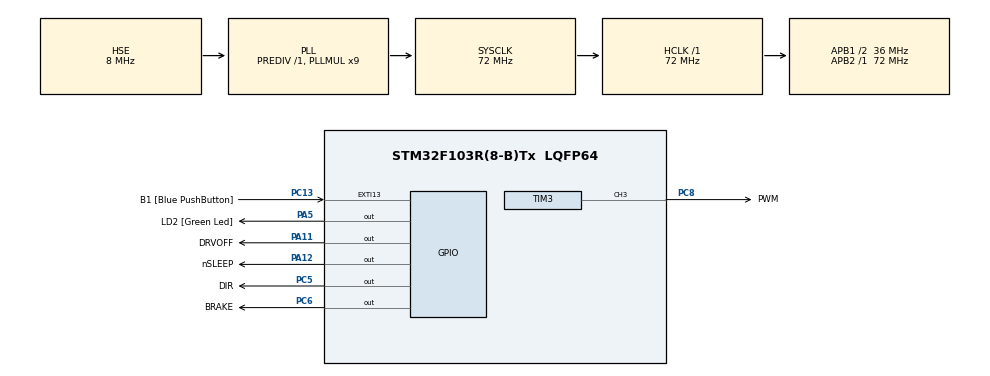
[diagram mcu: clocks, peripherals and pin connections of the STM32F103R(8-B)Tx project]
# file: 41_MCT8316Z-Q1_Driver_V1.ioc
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Mcu.Family=STM32F1
Mcu.Name=STM32F103R(8-B)Tx
Mcu.Package=LQFP64
NVIC.EXTI15_10_IRQn=true\:0\:0\:false\:false\:true\:true\:true\:true
NVIC.PriorityGroup=NVIC_PRIORITYGROUP_4
PA11.GPIO_Label=DRVOFF
PA11.Signal=GPIO_Output
PA12.GPIO_Label=nSLEEP
PA12.Signal=GPIO_Output
PA13.GPIO_Label=TMS
PA13.Mode=JTAG_5_pins
PA13.Signal=SYS_JTMS-SWDIO
PA14.GPIO_Label=TCK
PA14.Mode=JTAG_5_pins
PA14.Signal=SYS_JTCK-SWCLK
PA15.Mode=JTAG_5_pins
PA15.Signal=SYS_JTDI
PA5.GPIO_Label=LD2 [Green Led]
PA5.GPIO_ModeDefaultOutputPP=GPIO_MODE_OUTPUT_PP
PA5.GPIO_PuPd=GPIO_NOPULL
PA5.GPIO_Speed=GPIO_SPEED_FREQ_LOW
PA5.Signal=GPIO_Output
PB3.Mode=JTAG_5_pins
PB3.Signal=SYS_JTDO-TRACESWO
PB4.Mode=JTAG_5_pins
PB4.Signal=SYS_NJTRST
PC13-TAMPER-RTC.GPIO_Label=B1 [Blue PushButton]
PC13-TAMPER-RTC.GPIO_PuPd=GPIO_NOPULL
PC13-TAMPER-RTC.Signal=GPXTI13
PC14-OSC32_IN.Mode=LSE-External-Oscillator
PC14-OSC32_IN.Signal=RCC_OSC32_IN
PC15-OSC32_OUT.Mode=LSE-External-Oscillator
PC15-OSC32_OUT.Signal=RCC_OSC32_OUT
PC5.GPIO_Label=DIR
PC5.Signal=GPIO_Output
PC6.GPIO_Label=BRAKE
PC6.Signal=GPIO_Output
PC8.GPIO_Label=PWM
PC8.Signal=S_TIM3_CH3
PD0-OSC_IN.Mode=HSE-External-Oscillator
PD0-OSC_IN.Signal=RCC_OSC_IN
PD1-OSC_OUT.Mode=HSE-External-Oscillator
PD1-OSC_OUT.Signal=RCC_OSC_OUT
ProjectManager.HeapSize=0x200
ProjectManager.StackSize=0x400
ProjectManager.TargetToolchain=STM32CubeIDE
RCC.AHBFreq_Value=72000000
RCC.APB1CLKDivider=RCC_HCLK_DIV2
RCC.APB1Freq_Value=36000000
RCC.APB1TimFreq_Value=72000000
RCC.APB2Freq_Value=72000000
RCC.APB2TimFreq_Value=72000000
RCC.HCLKFreq_Value=72000000
RCC.PLLMUL=RCC_PLL_MUL9
RCC.PLLSourceVirtual=RCC_PLLSOURCE_HSE
RCC.RTCClockSelection=RCC_RTCCLKSOURCE_LSE
RCC.SYSCLKFreq_VALUE=72000000
RCC.SYSCLKSource=RCC_SYSCLKSOURCE_PLLCLK
RCC.USBFreq_Value=72000000
SH.S_TIM3_CH3.0=TIM3_CH3,PWM Generation3 CH3
TIM3.AutoReloadPreload=TIM_AUTORELOAD_PRELOAD_ENABLE
TIM3.Channel-PWM\ Generation3\ CH3=TIM_CHANNEL_3
TIM3.Period=359
VP_TIM3_VS_ClockSourceINT.Mode=Internal
board=NUCLEO-F103RB

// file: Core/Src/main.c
/* USER CODE BEGIN Header */
/**
  ******************************************************************************
  * @file           : main.c
  * @brief          : Main program body
  ******************************************************************************
  * @attention
  *
  * Copyright (c) 2025 STMicroelectronics.
  * All rights reserved.
  *
  * This software is licensed under terms that can be found in the LICENSE file
  * in the root directory of this software component.
  * If no LICENSE file comes with this software, it is provided AS-IS.
  *
  ******************************************************************************
  */
/* USER CODE END Header */
#include "main.h"
#include "tim.h"
#include "gpio.h"

/* USER CODE BEGIN PV */

int32_t PWM_DC = 0;

/* USER CODE END PV */

void SystemClock_Config(void);

int main(void)
{

  /* MCU Configuration--------------------------------------------------------*/

  /* Reset of all peripherals, Initializes the Flash interface and the Systick. */
  HAL_Init();

  /* Configure the system clock */
  SystemClock_Config();

  /* Initialize all configured peripherals */
  MX_GPIO_Init();
  MX_TIM3_Init();
  /* USER CODE BEGIN 2 */

  //////////__PWM__//////////
  // PWM input for motor control. Set the duty cycle and switching frequency of the
  // phase voltage of the motor.
  // 100% DutyCycle = 359
  //  50% DutyCycle = 180
  //  36%  = 36
  //   1%  = 4
  //   0% DutyCycle = 0
  HAL_TIM_PWM_Start(&htim3, TIM_CHANNEL_3 );
  TIM3->CCR3 = 180;

  //////////__BRAKE__//////////
  // High → Brake the motor when High by turning all low side MOSFETs ON
  // Low → normal operation
  HAL_GPIO_WritePin(BRAKE_GPIO_Port, BRAKE_Pin, GPIO_PIN_RESET);

  //////////__DIR__//////////
  // Direction pin for setting the direction of the motor rotation
  // to clockwise or counterclockwise.
  HAL_GPIO_WritePin(DIR_GPIO_Port, DIR_Pin, GPIO_PIN_RESET);

  //////////__nSLEEP__//////////
  // Driver nSLEEP. When this pin is logic low, the device goes into a low-power
  // sleep mode. An 20 to 40-μs low pulse can be used to reset fault conditions
  // without entering sleep mode.
  HAL_GPIO_WritePin(nSLEEP_GPIO_Port, nSLEEP_Pin, GPIO_PIN_SET);

  //////////__DRVOFF__//////////
  // When this pin is pulled high the six MOSFETs in the power stage are turned
  // OFF making all outputs Hi-Z.
  HAL_GPIO_WritePin(DRVOFF_GPIO_Port, DRVOFF_Pin, GPIO_PIN_RESET);

  HAL_Delay(500);

  /* USER CODE END 2 */

  /* Infinite loop */
  /* USER CODE BEGIN WHILE */
  while (1)
  {

	  /*
	  HAL_GPIO_WritePin(BRAKE_GPIO_Port, BRAKE_Pin, GPIO_PIN_SET);
	  HAL_Delay(500);
	  HAL_GPIO_WritePin(BRAKE_GPIO_Port, BRAKE_Pin, GPIO_PIN_RESET);
	  HAL_Delay(500);

	  HAL_GPIO_WritePin(DIR_GPIO_Port, DIR_Pin, GPIO_PIN_SET);
	  HAL_Delay(500);
	  HAL_GPIO_WritePin(DIR_GPIO_Port, DIR_Pin, GPIO_PIN_RESET);
	  HAL_Delay(500);

	  HAL_GPIO_WritePin(nSLEEP_GPIO_Port, nSLEEP_Pin, GPIO_PIN_RESET);
	  HAL_Delay(500);
	  HAL_GPIO_WritePin(nSLEEP_GPIO_Port, nSLEEP_Pin, GPIO_PIN_SET);
	  HAL_Delay(500);

	  HAL_GPIO_WritePin(DRVOFF_GPIO_Port, DRVOFF_Pin, GPIO_PIN_SET);
	  HAL_Delay(500);
	  HAL_GPIO_WritePin(DRVOFF_GPIO_Port, DRVOFF_Pin, GPIO_PIN_RESET);
	  HAL_Delay(500);

*/

	  HAL_GPIO_WritePin(LD2_GPIO_Port, LD2_Pin, GPIO_PIN_SET);
	  HAL_Delay(500);
	  HAL_GPIO_WritePin(LD2_GPIO_Port, LD2_Pin, GPIO_PIN_RESET);
	  HAL_Delay(500);

    /* USER CODE END WHILE */

  }
}

void SystemClock_Config(void)
{
  RCC_OscInitTypeDef RCC_OscInitStruct = {0};
  RCC_ClkInitTypeDef RCC_ClkInitStruct = {0};

  /** Initializes the RCC Oscillators according to the specified parameters
  * in the RCC_OscInitTypeDef structure.
  */
  RCC_OscInitStruct.OscillatorType = RCC_OSCILLATORTYPE_HSE;
  RCC_OscInitStruct.HSEState = RCC_HSE_ON;
  RCC_OscInitStruct.HSEPredivValue = RCC_HSE_PREDIV_DIV1;
  RCC_OscInitStruct.HSIState = RCC_HSI_ON;
  RCC_OscInitStruct.PLL.PLLState = RCC_PLL_ON;
  RCC_OscInitStruct.PLL.PLLSource = RCC_PLLSOURCE_HSE;
  RCC_OscInitStruct.PLL.PLLMUL = RCC_PLL_MUL9;
  if (HAL_RCC_OscConfig(&RCC_OscInitStruct) != HAL_OK)
  {
    Error_Handler();
  }

  /** Initializes the CPU, AHB and APB buses clocks
  */
  RCC_ClkInitStruct.ClockType = RCC_CLOCKTYPE_HCLK|RCC_CLOCKTYPE_SYSCLK
                              |RCC_CLOCKTYPE_PCLK1|RCC_CLOCKTYPE_PCLK2;
  RCC_ClkInitStruct.SYSCLKSource = RCC_SYSCLKSOURCE_PLLCLK;
  RCC_ClkInitStruct.AHBCLKDivider = RCC_SYSCLK_DIV1;
  RCC_ClkInitStruct.APB1CLKDivider = RCC_HCLK_DIV2;
  RCC_ClkInitStruct.APB2CLKDivider = RCC_HCLK_DIV1;

  if (HAL_RCC_ClockConfig(&RCC_ClkInitStruct, FLASH_LATENCY_2) != HAL_OK)
  {
    Error_Handler();
  }
}

void Error_Handler(void)
{
  __disable_irq();
  while (1)
  {
  }
}
